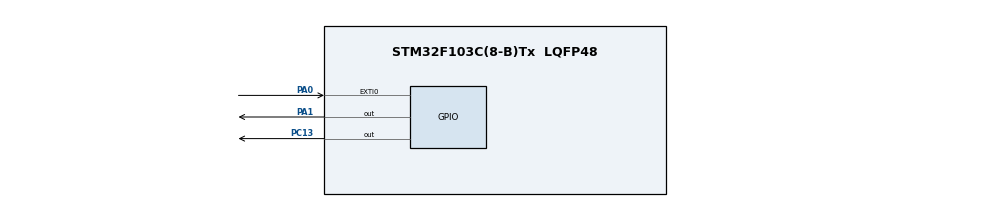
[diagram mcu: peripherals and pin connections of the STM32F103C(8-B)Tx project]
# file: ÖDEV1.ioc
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Mcu.Family=STM32F1
Mcu.Name=STM32F103C(8-B)Tx
Mcu.Package=LQFP48
NVIC.EXTI0_IRQn=true\:0\:0\:false\:false\:true\:true\:true\:true
NVIC.PriorityGroup=NVIC_PRIORITYGROUP_4
NVIC.TIM2_IRQn=true\:0\:0\:false\:false\:true\:true\:true\:true
PA0-WKUP.GPIO_ModeDefaultEXTI=GPIO_MODE_IT_FALLING
PA0-WKUP.GPIO_PuPd=GPIO_PULLUP
PA0-WKUP.Signal=GPXTI0
PA1.Signal=GPIO_Output
PC13-TAMPER-RTC.Signal=GPIO_Output
ProjectManager.HeapSize=0x200
ProjectManager.StackSize=0x400
ProjectManager.TargetToolchain=Makefile
RCC.APB1Freq_Value=8000000
RCC.APB2Freq_Value=8000000
TIM2.Period=999
TIM2.Prescaler=7999
VP_SYS_VS_ND.Mode=No_Debug
VP_TIM2_VS_ClockSourceINT.Mode=Internal
board=custom

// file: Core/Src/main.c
/* USER CODE BEGIN Header */
/**
  ******************************************************************************
  * @file           : main.c
  * @brief          : Main program body
  ******************************************************************************
  * @attention
  *
  * Copyright (c) 2026 STMicroelectronics.
  * All rights reserved.
  *
  * This software is licensed under terms that can be found in the LICENSE file
  * in the root directory of this software component.
  * If no LICENSE file comes with this software, it is provided AS-IS.
  *
  ******************************************************************************
  */
/* USER CODE END Header */
#include "main.h"
#include <stm32f100xb.h>

/* USER CODE BEGIN PD */
#define FLASH_ADDR 0x0800FC00
/* USER CODE END PD */

TIM_HandleTypeDef htim2;

/* USER CODE BEGIN PV */

uint32_t blink_count = 4;             // Ödev Madde (d): Başlangıç değeri 4
unsigned int prev_tick_count = 0;     // PDF 5: Buton ark (bouncing) koruması için
uint32_t button_press_start = 0;      // Ödev Madde (g): 3 saniye ölçümü için
uint8_t button_held = 0;

/* USER CODE END PV */

void SystemClock_Config(void);
static void MX_GPIO_Init(void);
static void MX_TIM2_Init(void);

/* USER CODE BEGIN 0 */

void Write_Flash(uint32_t data) {
    HAL_FLASH_Unlock(); // Yazma işleminden önce kilidi aç

    FLASH_EraseInitTypeDef EraseInitStruct;
    uint32_t PageError = 0;

    // Flash bellekte bir adrese yazmadan önce o sayfayı silmek zorundayız
    EraseInitStruct.TypeErase = FLASH_TYPEERASE_PAGES;
    EraseInitStruct.PageAddress = FLASH_ADDR; // Belirlediğimiz 63. sayfa adresi
    EraseInitStruct.NbPages = 1;

    HAL_FLASHEx_Erase(&EraseInitStruct, &PageError); // Sayfayı temizle

    // Veriyi (blink_count) flash belleğe yaz
    HAL_FLASH_Program(FLASH_TYPEPROGRAM_WORD, FLASH_ADDR, data);

    HAL_FLASH_Lock(); // İşlem bitince güvenliğiniz için kilidi geri kapat
}

// Madde (e) ve (f): Flash bellekten veri okuma fonksiyonu
uint32_t Read_Flash(void) {
    // Belirlediğimiz adresteki değeri doğrudan oku
    return *(__IO uint32_t *)FLASH_ADDR;
}

/* USER CODE END 0 */

int main(void)
{

  /* MCU Configuration--------------------------------------------------------*/

  /* Reset of all peripherals, Initializes the Flash interface and the Systick. */
  HAL_Init();

  /* Configure the system clock */
  SystemClock_Config();

  /* Initialize all configured peripherals */
  MX_GPIO_Init();
  MX_TIM2_Init();
  /* USER CODE BEGIN 2 */

  HAL_GPIO_WritePin(GPIOA, GPIO_PIN_1, GPIO_PIN_RESET);

// Madde (e) & (f): Başlangıçta Flash'tan blink_count değerini oku
uint32_t saved_val = Read_Flash();

// Madde (f): Eğer bellek boşsa (ilk kez çalışıyorsa 0xFFFFFFFF döner)
if (saved_val > 7) {
    blink_count = 4; // Değeri fabrika ayarı olan 4 yap
    Write_Flash(blink_count); // Flash'a bu değeri kaydet
} else {
    blink_count = saved_val; // Bellekteki geçerli değeri kullan
}

// Madde (a): TIM2 Zamanlayıcı kesmesini (interrupt) başlat [cite: 3218, 3225]
HAL_TIM_Base_Start_IT(&htim2);

  /* USER CODE END 2 */

  /* Infinite loop */
  /* USER CODE BEGIN WHILE */
  while (1)
  {
    if (HAL_GPIO_ReadPin(GPIOA, GPIO_PIN_0) == GPIO_PIN_RESET)
    {
        // Eğer süre ölçümü henüz başlamadıysa şimdi başlat
        if (button_press_start == 0)
        {
            button_press_start = HAL_GetTick(); // Mevcut milisaniyeyi kaydet
        }
        // 3 saniye (3000 ms) geçtiyse ve henüz sıfırlama yapılmadıysa
        else if ((HAL_GetTick() - button_press_start >= 3000) && !button_held)
        {
            button_held = 1;      // Tekrar tekrar çalışmasın diye işaretle
            blink_count = 4;      // Fabrika ayarlarına dön
            Write_Flash(blink_count); // Yeni değeri kalıcı hafızaya yaz
        }
    }
    // Buton bırakıldığında (Cımbız çekildiğinde) süreleri sıfırla
    else
    {
        button_press_start = 0;
        button_held = 0;
    }

    /* USER CODE END WHILE */

  }
}

void SystemClock_Config(void)
{
  RCC_OscInitTypeDef RCC_OscInitStruct = {0};
  RCC_ClkInitTypeDef RCC_ClkInitStruct = {0};

  /** Initializes the RCC Oscillators according to the specified parameters
  * in the RCC_OscInitTypeDef structure.
  */
  RCC_OscInitStruct.OscillatorType = RCC_OSCILLATORTYPE_HSI;
  RCC_OscInitStruct.HSIState = RCC_HSI_ON;
  RCC_OscInitStruct.HSICalibrationValue = RCC_HSICALIBRATION_DEFAULT;
  RCC_OscInitStruct.PLL.PLLState = RCC_PLL_NONE;
  if (HAL_RCC_OscConfig(&RCC_OscInitStruct) != HAL_OK)
  {
    Error_Handler();
  }

  /** Initializes the CPU, AHB and APB buses clocks
  */
  RCC_ClkInitStruct.ClockType = RCC_CLOCKTYPE_HCLK|RCC_CLOCKTYPE_SYSCLK
                              |RCC_CLOCKTYPE_PCLK1|RCC_CLOCKTYPE_PCLK2;
  RCC_ClkInitStruct.SYSCLKSource = RCC_SYSCLKSOURCE_HSI;
  RCC_ClkInitStruct.AHBCLKDivider = RCC_SYSCLK_DIV1;
  RCC_ClkInitStruct.APB1CLKDivider = RCC_HCLK_DIV1;
  RCC_ClkInitStruct.APB2CLKDivider = RCC_HCLK_DIV1;

  if (HAL_RCC_ClockConfig(&RCC_ClkInitStruct, FLASH_LATENCY_0) != HAL_OK)
  {
    Error_Handler();
  }
}

static void MX_TIM2_Init(void)
{

  TIM_ClockConfigTypeDef sClockSourceConfig = {0};
  TIM_MasterConfigTypeDef sMasterConfig = {0};

  htim2.Instance = TIM2;
  htim2.Init.Prescaler = 7999;
  htim2.Init.CounterMode = TIM_COUNTERMODE_UP;
  htim2.Init.Period = 999;
  htim2.Init.ClockDivision = TIM_CLOCKDIVISION_DIV1;
  htim2.Init.AutoReloadPreload = TIM_AUTORELOAD_PRELOAD_DISABLE;
  if (HAL_TIM_Base_Init(&htim2) != HAL_OK)
  {
    Error_Handler();
  }
  sClockSourceConfig.ClockSource = TIM_CLOCKSOURCE_INTERNAL;
  if (HAL_TIM_ConfigClockSource(&htim2, &sClockSourceConfig) != HAL_OK)
  {
    Error_Handler();
  }
  sMasterConfig.MasterOutputTrigger = TIM_TRGO_RESET;
  sMasterConfig.MasterSlaveMode = TIM_MASTERSLAVEMODE_DISABLE;
  if (HAL_TIMEx_MasterConfigSynchronization(&htim2, &sMasterConfig) != HAL_OK)
  {
    Error_Handler();
  }

}

static void MX_GPIO_Init(void)
{
  GPIO_InitTypeDef GPIO_InitStruct = {0};

  /* GPIO Ports Clock Enable */
  __HAL_RCC_GPIOC_CLK_ENABLE();
  __HAL_RCC_GPIOA_CLK_ENABLE();

  /*Configure GPIO pin Output Level */
  HAL_GPIO_WritePin(GPIOC, GPIO_PIN_13, GPIO_PIN_RESET);

  /*Configure GPIO pin Output Level */
  HAL_GPIO_WritePin(GPIOA, GPIO_PIN_1, GPIO_PIN_RESET);

  /*Configure GPIO pin : PC13 */
  GPIO_InitStruct.Pin = GPIO_PIN_13;
  GPIO_InitStruct.Mode = GPIO_MODE_OUTPUT_PP;
  GPIO_InitStruct.Pull = GPIO_NOPULL;
  GPIO_InitStruct.Speed = GPIO_SPEED_FREQ_LOW;
  HAL_GPIO_Init(GPIOC, &GPIO_InitStruct);

  /*Configure GPIO pin : PA0 */
  GPIO_InitStruct.Pin = GPIO_PIN_0;
  GPIO_InitStruct.Mode = GPIO_MODE_IT_FALLING;
  GPIO_InitStruct.Pull = GPIO_PULLUP;
  HAL_GPIO_Init(GPIOA, &GPIO_InitStruct);

  /*Configure GPIO pin : PA1 */
  GPIO_InitStruct.Pin = GPIO_PIN_1;
  GPIO_InitStruct.Mode = GPIO_MODE_OUTPUT_PP;
  GPIO_InitStruct.Pull = GPIO_NOPULL;
  GPIO_InitStruct.Speed = GPIO_SPEED_FREQ_LOW;
  HAL_GPIO_Init(GPIOA, &GPIO_InitStruct);

  /* EXTI interrupt init*/
  HAL_NVIC_SetPriority(EXTI0_IRQn, 0, 0);
  HAL_NVIC_EnableIRQ(EXTI0_IRQn);

}

/* USER CODE BEGIN 4 */

// Madde (b) ve (c): TIM2 Zamanlayıcı Kesmesi
// Bu fonksiyon her 1 saniyede bir otomatik olarak çalışır.
void HAL_TIM_PeriodElapsedCallback(TIM_HandleTypeDef *htim)
{
    if (htim->Instance == TIM2)
    {
        // PC13 pinindeki LED'in durumunu değiştir (açık/kapalı)
        HAL_GPIO_TogglePin(GPIOC, GPIO_PIN_13);
    }
}

// Madde (d): Buton Kesmesi (Cımbızla dokunma anı)
void HAL_GPIO_EXTI_Callback(uint16_t GPIO_Pin)
{
    // PDF 5 (Sayfa 47): Buton ark (bouncing) koruması
    unsigned int cur_tick_count = HAL_GetTick();
    if(cur_tick_count - prev_tick_count < 300)
    {
        return; // 300ms içinde gelen sinyalleri görmezden gel
    }
    else
    {
        prev_tick_count = cur_tick_count;
    }

    if (GPIO_Pin == GPIO_PIN_0)
    {
        // Madde (d): blink_count değerini 1 artır
        blink_count++;

        // Değer 7'yi geçerse tekrar 4'e dön
        if (blink_count > 7)
        {
            blink_count = 4;
        }

        // Madde (e): Yeni değeri hemen kalıcı hafızaya (Flash) kaydet
        Write_Flash(blink_count);
    }
}
/* USER CODE END 4 */

void Error_Handler(void)
{
  __disable_irq();
  while (1)
  {
  }
}
